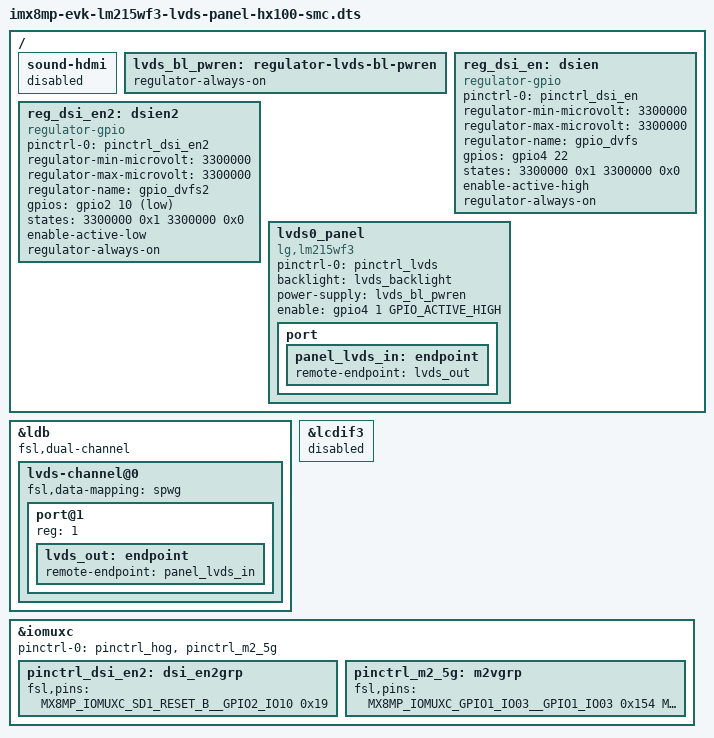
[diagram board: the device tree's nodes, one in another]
// SPDX-License-Identifier: GPL-2.0+
/*
 * Copyright 2020 NXP
 */

#include "imx8mp-evk.dts"

/delete-node/ &reg_m2_3v3;
/ {
	sound-hdmi {
		status = "disabled";
	};
	 lvds_bl_pwren: regulator-lvds-bl-pwren {
		regulator-always-on;
	};

	reg_dsi_en: dsien {
		compatible = "regulator-gpio";
		pinctrl-names = "default";
		pinctrl-0 = <&pinctrl_dsi_en>;
		regulator-min-microvolt = <3300000>;
		regulator-max-microvolt = <3300000>;
		regulator-name = "gpio_dvfs";
		gpios = <&gpio4 22 GPIO_ACTIVE_HIGH>;
		states = <3300000 0x1 3300000 0x0>;
		enable-active-high;
		regulator-always-on;
	};

	reg_dsi_en2: dsien2 {
		compatible = "regulator-gpio";
		pinctrl-names = "default";
		pinctrl-0 = <&pinctrl_dsi_en2>;
		regulator-min-microvolt = <3300000>;
		regulator-max-microvolt = <3300000>;
		regulator-name = "gpio_dvfs2";
		gpios = <&gpio2 10 GPIO_ACTIVE_LOW>;
		states = <3300000 0x1 3300000 0x0>;
		enable-active-low;
		regulator-always-on;
	};

	lvds0_panel {
		compatible = "lg,lm215wf3";
		pinctrl-names = "default";
		pinctrl-0 = <&pinctrl_lvds>;
		backlight = <&lvds_backlight>;
		power-supply = <&lvds_bl_pwren>;
        enable = <&gpio4 1 GPIO_ACTIVE_HIGH >;
		port {
			panel_lvds_in: endpoint {
				remote-endpoint = <&lvds_out>;
			};
		};
	};
};

/delete-node/ &lvds_bridge;
/delete-node/ &adv_bridge;
/delete-node/ &dsim_to_adv7535;

&ldb {
	fsl,dual-channel;

	lvds-channel@0 {
		fsl,data-mapping = "spwg";

		/delete-node/ port@1;

		port@1 {
			reg = <1>;

			lvds_out: endpoint {
				remote-endpoint = <&panel_lvds_in>;
			};
		};
	};
};

&lcdif3 {
	status = "disabled";
};

&iomuxc {
	pinctrl-names = "default";
	pinctrl-0 = <&pinctrl_hog>,<&pinctrl_m2_5g>;

	pinctrl_dsi_en2: dsi_en2grp {
		fsl,pins = <
			MX8MP_IOMUXC_SD1_RESET_B__GPIO2_IO10		0x19
		>;
	};

	pinctrl_m2_5g: m2vgrp {
		/delete-property/ fsl,pins; 
		fsl,pins = <
			MX8MP_IOMUXC_GPIO1_IO03__GPIO1_IO03		0x154
			MX8MP_IOMUXC_NAND_DATA00__GPIO3_IO06	0x154
			MX8MP_IOMUXC_NAND_DATA01__GPIO3_IO07	0x154
			MX8MP_IOMUXC_NAND_DATA02__GPIO3_IO08	0x154
			MX8MP_IOMUXC_NAND_DATA03__GPIO3_IO09	0x154
			//MX8MP_IOMUXC_SD1_RESET_B__GPIO2_IO10	0x154
		>;
	};
};
